# iqn_aid register map
Vendor: Texas Instruments
Peripheral module from a debugger description file (folder Keystone2).
Registers are 32-bit, read-only, no defined reset value unless marked. A register's access mark holds for its fields unless they carry their own. Offsets are as the file gives them; lines under a group give offsets from that group; [hi:lo] are bit positions; {n}, {i} and the like mark numbered series; 'fields as' and 'values as' point back to an identical list; <NAME> marks a mode.

## IQN_AID (part 1 of 2)
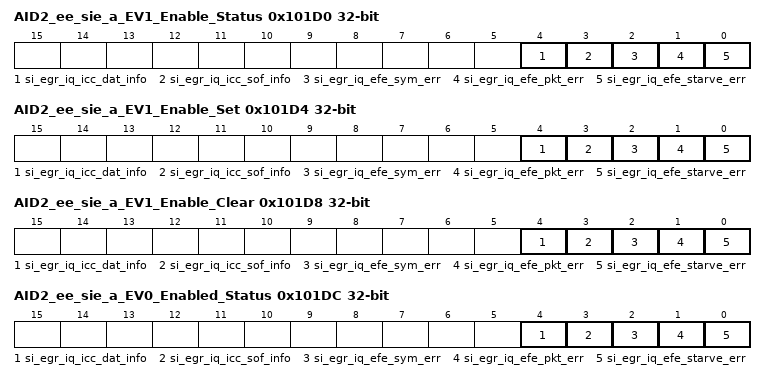
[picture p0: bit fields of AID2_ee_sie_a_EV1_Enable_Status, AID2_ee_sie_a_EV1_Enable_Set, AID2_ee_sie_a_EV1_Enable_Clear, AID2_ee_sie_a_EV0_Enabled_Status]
0x101D0 AID2_ee_sie_a_EV1_Enable_Status — (1 of 1, stride 0)
  [4] si_egr_iq_icc_dat_info — When set allows the corresponding bit in the raw_status register to generate the intr1_sts interrupt. Read only.
  [3] si_egr_iq_icc_sof_info — When set allows the corresponding bit in the raw_status register to generate the intr1_sts interrupt. Read only.
  [2] si_egr_iq_efe_sym_err — When set allows the corresponding bit in the raw_status register to generate the intr1_sts interrupt. Read only.
  [1] si_egr_iq_efe_pkt_err — When set allows the corresponding bit in the raw_status register to generate the intr1_sts interrupt. Read only.
  [0] si_egr_iq_efe_starve_err — When set allows the corresponding bit in the raw_status register to generate the intr1_sts interrupt. Read only.
0x101D4 AID2_ee_sie_a_EV1_Enable_Set wo — (1 of 1, stride 0)
  [4] si_egr_iq_icc_dat_info — Sets the corresponding bit in the intr1_status register when set. Write only, self-clears.
  [3] si_egr_iq_icc_sof_info — Sets the corresponding bit in the intr1_status register when set. Write only, self-clears.
  [2] si_egr_iq_efe_sym_err — Sets the corresponding bit in the intr1_status register when set. Write only, self-clears.
  [1] si_egr_iq_efe_pkt_err — Sets the corresponding bit in the intr1_status register when set. Write only, self-clears.
  [0] si_egr_iq_efe_starve_err — Sets the corresponding bit in the intr1_status register when set. Write only, self-clears.
0x101D8 AID2_ee_sie_a_EV1_Enable_Clear wo — (1 of 1, stride 0)
  [4] si_egr_iq_icc_dat_info — Clears the corresponding bit in the intr1_status register when set. Write only, self-clears.
  [3] si_egr_iq_icc_sof_info — Clears the corresponding bit in the intr1_status register when set. Write only, self-clears.
  [2] si_egr_iq_efe_sym_err — Clears the corresponding bit in the intr1_status register when set. Write only, self-clears.
  [1] si_egr_iq_efe_pkt_err — Clears the corresponding bit in the intr1_status register when set. Write only, self-clears.
  [0] si_egr_iq_efe_starve_err — Clears the corresponding bit in the intr1_status register when set. Write only, self-clears.
0x101DC AID2_ee_sie_a_EV0_Enabled_Status — (1 of 1, stride 0)
  [4] si_egr_iq_icc_dat_info — AND-ed raw_status bits with the corresponding bit in the enable_status register. Read only.
  [3] si_egr_iq_icc_sof_info — AND-ed raw_status bits with the corresponding bit in the enable_status register. Read only.
  [2] si_egr_iq_efe_sym_err — AND-ed raw_status bits with the corresponding bit in the enable_status register. Read only.
  [1] si_egr_iq_efe_pkt_err — AND-ed raw_status bits with the corresponding bit in the enable_status register. Read only.
  [0] si_egr_iq_efe_starve_err — AND-ed raw_status bits with the corresponding bit in the enable_status register. Read only.
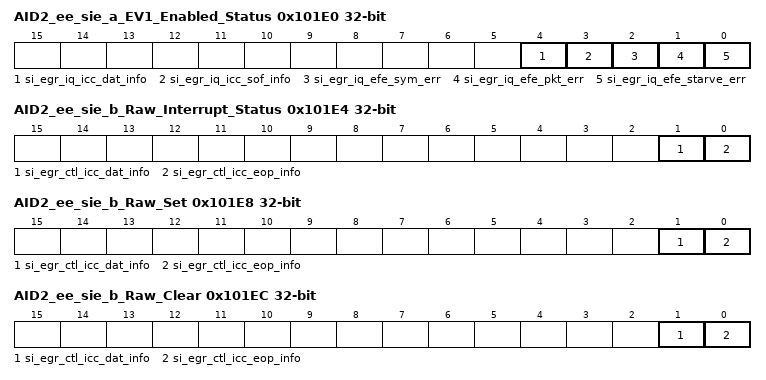
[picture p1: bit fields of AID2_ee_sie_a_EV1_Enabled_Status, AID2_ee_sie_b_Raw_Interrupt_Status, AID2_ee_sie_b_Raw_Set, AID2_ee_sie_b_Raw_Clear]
0x101E0 AID2_ee_sie_a_EV1_Enabled_Status — (1 of 1, stride 0)
  [4] si_egr_iq_icc_dat_info — AND-ed raw_status bits with the corresponding bit in the intr1_status register. Read only.
  [3] si_egr_iq_icc_sof_info — AND-ed raw_status bits with the corresponding bit in the intr1_status register. Read only.
  [2] si_egr_iq_efe_sym_err — AND-ed raw_status bits with the corresponding bit in the intr1_status register. Read only.
  [1] si_egr_iq_efe_pkt_err — AND-ed raw_status bits with the corresponding bit in the intr1_status register. Read only.
  [0] si_egr_iq_efe_starve_err — AND-ed raw_status bits with the corresponding bit in the intr1_status register. Read only.
0x101E4 AID2_ee_sie_b_Raw_Interrupt_Status — (1 of 1, stride 0)
  [1] si_egr_ctl_icc_dat_info — SI Egress CTL transmitted data to ICC
  [0] si_egr_ctl_icc_eop_info — SI Egress CTL transmitted EOP to ICC
0x101E8 AID2_ee_sie_b_Raw_Set wo — (1 of 1, stride 0)
  [1] si_egr_ctl_icc_dat_info — Sets the corresponding bit in the raw_status register when set. Write only, self-clears.
  [0] si_egr_ctl_icc_eop_info — Sets the corresponding bit in the raw_status register when set. Write only, self-clears.
0x101EC AID2_ee_sie_b_Raw_Clear wo — (1 of 1, stride 0)
  [1] si_egr_ctl_icc_dat_info — Clears the corresponding bit in the raw_status register when set. Write only, self-clears.
  [0] si_egr_ctl_icc_eop_info — Clears the corresponding bit in the raw_status register when set. Write only, self-clears.
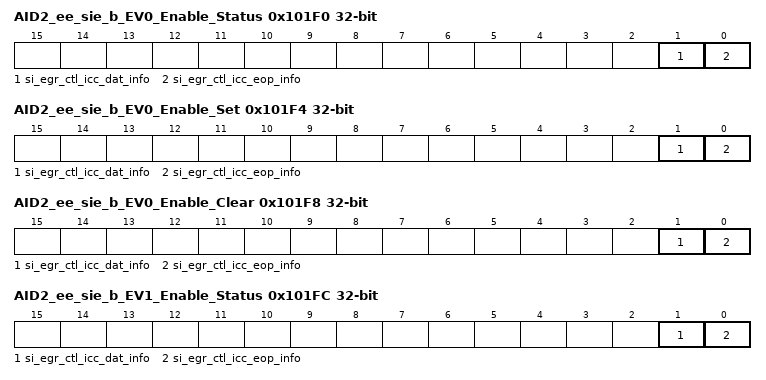
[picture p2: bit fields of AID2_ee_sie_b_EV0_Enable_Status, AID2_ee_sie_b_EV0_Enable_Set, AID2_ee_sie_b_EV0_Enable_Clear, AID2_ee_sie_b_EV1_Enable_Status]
0x101F0 AID2_ee_sie_b_EV0_Enable_Status — (1 of 1, stride 0)
  [1] si_egr_ctl_icc_dat_info — When set allows the corresponding bit in the raw_status register to generate the intr_sts interrupt. Read only.
  [0] si_egr_ctl_icc_eop_info — When set allows the corresponding bit in the raw_status register to generate the intr_sts interrupt. Read only.
0x101F4 AID2_ee_sie_b_EV0_Enable_Set wo — (1 of 1, stride 0)
  [1] si_egr_ctl_icc_dat_info — Sets the corresponding bit in the enable register when set. Write only, self-clears.
  [0] si_egr_ctl_icc_eop_info — Sets the corresponding bit in the enable register when set. Write only, self-clears.
0x101F8 AID2_ee_sie_b_EV0_Enable_Clear wo — (1 of 1, stride 0)
  [1] si_egr_ctl_icc_dat_info — Clears the corresponding bit in the enable register when set. Write only, self-clears.
  [0] si_egr_ctl_icc_eop_info — Clears the corresponding bit in the enable register when set. Write only, self-clears.
0x101FC AID2_ee_sie_b_EV1_Enable_Status — (1 of 1, stride 0)
  [1] si_egr_ctl_icc_dat_info — When set allows the corresponding bit in the raw_status register to generate the intr1_sts interrupt. Read only.
  [0] si_egr_ctl_icc_eop_info — When set allows the corresponding bit in the raw_status register to generate the intr1_sts interrupt. Read only.
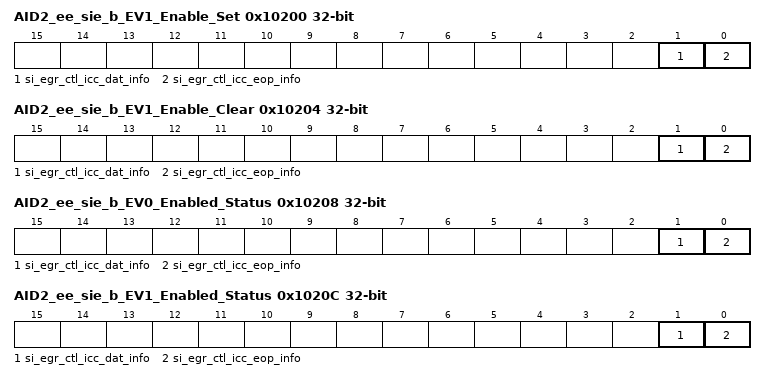
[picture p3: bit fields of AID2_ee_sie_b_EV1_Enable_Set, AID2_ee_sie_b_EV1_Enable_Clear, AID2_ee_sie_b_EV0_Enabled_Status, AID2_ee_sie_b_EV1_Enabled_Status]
0x10200 AID2_ee_sie_b_EV1_Enable_Set wo — (1 of 1, stride 0)
  [1] si_egr_ctl_icc_dat_info — Sets the corresponding bit in the intr1_status register when set. Write only, self-clears.
  [0] si_egr_ctl_icc_eop_info — Sets the corresponding bit in the intr1_status register when set. Write only, self-clears.
0x10204 AID2_ee_sie_b_EV1_Enable_Clear wo — (1 of 1, stride 0)
  [1] si_egr_ctl_icc_dat_info — Clears the corresponding bit in the intr1_status register when set. Write only, self-clears.
  [0] si_egr_ctl_icc_eop_info — Clears the corresponding bit in the intr1_status register when set. Write only, self-clears.
0x10208 AID2_ee_sie_b_EV0_Enabled_Status — (1 of 1, stride 0)
  [1] si_egr_ctl_icc_dat_info — AND-ed raw_status bits with the corresponding bit in the enable_status register. Read only.
  [0] si_egr_ctl_icc_eop_info — AND-ed raw_status bits with the corresponding bit in the enable_status register. Read only.
0x1020C AID2_ee_sie_b_EV1_Enabled_Status — (1 of 1, stride 0)
  [1] si_egr_ctl_icc_dat_info — AND-ed raw_status bits with the corresponding bit in the intr1_status register. Read only.
  [0] si_egr_ctl_icc_eop_info — AND-ed raw_status bits with the corresponding bit in the intr1_status register. Read only.
0x10210 AID2_ee_sie_c_Raw_Interrupt_Status — (1 of 1, stride 0)
  [15:0] si_egr_ctl_icc_sop_info — SI Egress CTL per channel SOP transmitted to ICC
0x10214 AID2_ee_sie_c_Raw_Set wo — (1 of 1, stride 0)
  [15:0] si_egr_ctl_icc_sop_info — Sets the corresponding bit in the raw_status register when set. Write only, self-clears.
0x10218 AID2_ee_sie_c_Raw_Clear wo — (1 of 1, stride 0)
  [15:0] si_egr_ctl_icc_sop_info — Clears the corresponding bit in the raw_status register when set. Write only, self-clears.
0x1021C AID2_ee_sie_c_EV0_Enable_Status — (1 of 1, stride 0)
  [15:0] si_egr_ctl_icc_sop_info — When set allows the corresponding bit in the raw_status register to generate the intr_sts interrupt. Read only.
0x10220 AID2_ee_sie_c_EV0_Enable_Set wo — (1 of 1, stride 0)
  [15:0] si_egr_ctl_icc_sop_info — Sets the corresponding bit in the enable register when set. Write only, self-clears.
0x10224 AID2_ee_sie_c_EV0_Enable_Clear wo — (1 of 1, stride 0)
  [15:0] si_egr_ctl_icc_sop_info — Clears the corresponding bit in the enable register when set. Write only, self-clears.
0x10228 AID2_ee_sie_c_EV1_Enable_Status — (1 of 1, stride 0)
  [15:0] si_egr_ctl_icc_sop_info — When set allows the corresponding bit in the raw_status register to generate the intr1_sts interrupt. Read only.
0x1022C AID2_ee_sie_c_EV1_Enable_Set wo — (1 of 1, stride 0)
  [15:0] si_egr_ctl_icc_sop_info — Sets the corresponding bit in the intr1_status register when set. Write only, self-clears.
0x10230 AID2_ee_sie_c_EV1_Enable_Clear wo — (1 of 1, stride 0)
  [15:0] si_egr_ctl_icc_sop_info — Clears the corresponding bit in the intr1_status register when set. Write only, self-clears.
0x10234 AID2_ee_sie_c_EV0_Enabled_Status — (1 of 1, stride 0)
  [15:0] si_egr_ctl_icc_sop_info — AND-ed raw_status bits with the corresponding bit in the enable_status register. Read only.
0x10238 AID2_ee_sie_c_EV1_Enabled_Status — (1 of 1, stride 0)
  [15:0] si_egr_ctl_icc_sop_info — AND-ed raw_status bits with the corresponding bit in the intr1_status register. Read only.
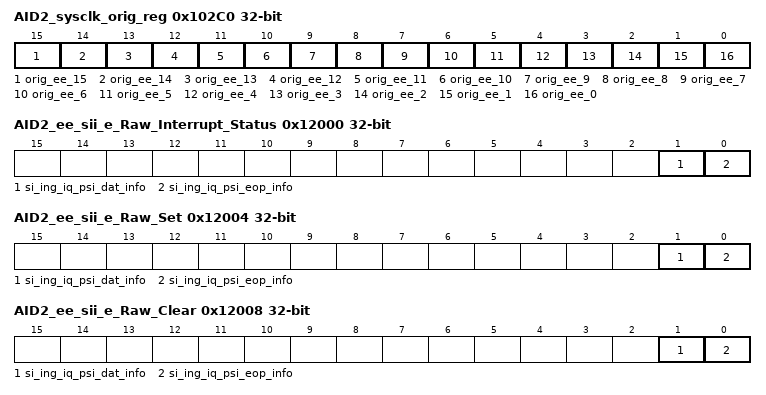
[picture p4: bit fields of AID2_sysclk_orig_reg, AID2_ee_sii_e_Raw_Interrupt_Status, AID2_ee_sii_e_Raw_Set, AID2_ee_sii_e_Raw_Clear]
0x102C0 AID2_sysclk_orig_reg — (1 of 1, stride 0)
  [15] orig_ee_15 — Undefined for AID2. Always read as 0.
  [14] orig_ee_14 — Undefined for AID2. Always read as 0.
  [13] orig_ee_13 — Undefined for AID2. Always read as 0.
  [12] orig_ee_12 — If set a bit is set in the ee_sie_c register.
  [11] orig_ee_11 — If set a bit is set in the ee_sie_b register.
  [10] orig_ee_10 — If set a bit is set in the ee_sie_a register.
  [9] orig_ee_9 — Undefined for AID2. Always read as 0.
  [8] orig_ee_8 — Undefined for AID2. Always read as 0.
  [7] orig_ee_7 — Undefined for AID2. Always read as 0.
  [6] orig_ee_6 — If set a bit is set in the ee_sii_d register.
  [5] orig_ee_5 — Undefined for AID2. Always read as 0.
  [4] orig_ee_4 — Undefined for AID2. Always read as 0.
  [3] orig_ee_3 — Undefined for AID2. Always read as 0.
  [2] orig_ee_2 — If set a bit is set in the ee_sii_c register.
  [1] orig_ee_1 — If set a bit is set in the ee_sii_b register.
  [0] orig_ee_0 — If set a bit is set in the ee_sii_a register.
0x11000 AID2_dfe_ee_a_Raw_Interrupt_Status — (1 of 1, stride 0)
  [1:0] dfe_iqn_aid2_err — DFE error interrupts
0x11004 AID2_dfe_ee_a_Raw_Set wo — (1 of 1, stride 0)
  [1:0] dfe_iqn_aid2_err — Sets the corresponding bit in the raw_status register when set. Write only, self-clears.
0x11008 AID2_dfe_ee_a_Raw_Clear wo — (1 of 1, stride 0)
  [1:0] dfe_iqn_aid2_err — Clears the corresponding bit in the raw_status register when set. Write only, self-clears.
0x1100C AID2_dfe_ee_a_EV0_Enable_Status — (1 of 1, stride 0)
  [1:0] dfe_iqn_aid2_err — When set allows the corresponding bit in the raw_status register to generate the intr_sts interrupt. Read only.
0x11010 AID2_dfe_ee_a_EV0_Enable_Set wo — (1 of 1, stride 0)
  [1:0] dfe_iqn_aid2_err — Sets the corresponding bit in the enable register when set. Write only, self-clears.
0x11014 AID2_dfe_ee_a_EV0_Enable_Clear wo — (1 of 1, stride 0)
  [1:0] dfe_iqn_aid2_err — Clears the corresponding bit in the enable register when set. Write only, self-clears.
0x11018 AID2_dfe_ee_a_EV1_Enable_Status — (1 of 1, stride 0)
  [1:0] dfe_iqn_aid2_err — When set allows the corresponding bit in the raw_status register to generate the intr1_sts interrupt. Read only.
0x1101C AID2_dfe_ee_a_EV1_Enable_Set wo — (1 of 1, stride 0)
  [1:0] dfe_iqn_aid2_err — Sets the corresponding bit in the intr1_status register when set. Write only, self-clears.
0x11020 AID2_dfe_ee_a_EV1_Enable_Clear wo — (1 of 1, stride 0)
  [1:0] dfe_iqn_aid2_err — Clears the corresponding bit in the intr1_status register when set. Write only, self-clears.
0x11024 AID2_dfe_ee_a_EV0_Enabled_Status — (1 of 1, stride 0)
  [1:0] dfe_iqn_aid2_err — AND-ed raw_status bits with the corresponding bit in the enable_status register. Read only.
0x11028 AID2_dfe_ee_a_EV1_Enabled_Status — (1 of 1, stride 0)
  [1:0] dfe_iqn_aid2_err — AND-ed raw_status bits with the corresponding bit in the intr1_status register. Read only.
0x12000 AID2_ee_sii_e_Raw_Interrupt_Status — (1 of 1, stride 0)
  [1] si_ing_iq_psi_dat_info — SI Ingress IQ data transmitted to PSI
  [0] si_ing_iq_psi_eop_info — SI Ingress IQ EOP transmitted to PSI
0x12004 AID2_ee_sii_e_Raw_Set wo — (1 of 1, stride 0)
  [1] si_ing_iq_psi_dat_info — Sets the corresponding bit in the raw_status register when set. Write only, self-clears.
  [0] si_ing_iq_psi_eop_info — Sets the corresponding bit in the raw_status register when set. Write only, self-clears.
0x12008 AID2_ee_sii_e_Raw_Clear wo — (1 of 1, stride 0)
  [1] si_ing_iq_psi_dat_info — Clears the corresponding bit in the raw_status register when set. Write only, self-clears.
  [0] si_ing_iq_psi_eop_info — Clears the corresponding bit in the raw_status register when set. Write only, self-clears.
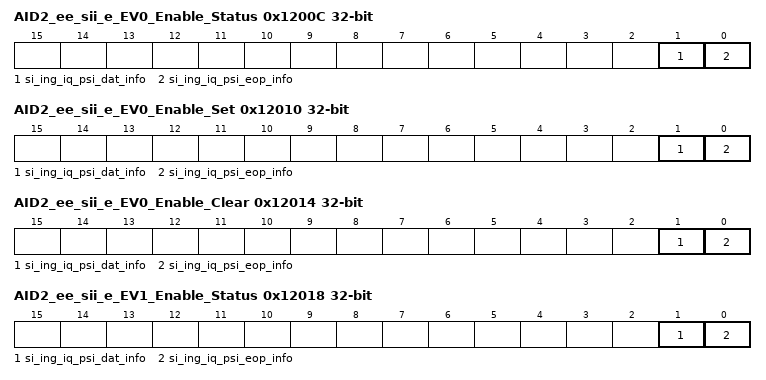
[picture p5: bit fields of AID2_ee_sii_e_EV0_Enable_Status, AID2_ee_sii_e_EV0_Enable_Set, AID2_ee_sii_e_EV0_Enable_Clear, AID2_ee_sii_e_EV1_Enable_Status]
0x1200C AID2_ee_sii_e_EV0_Enable_Status — (1 of 1, stride 0)
  [1] si_ing_iq_psi_dat_info — When set allows the corresponding bit in the raw_status register to generate the intr_sts interrupt. Read only.
  [0] si_ing_iq_psi_eop_info — When set allows the corresponding bit in the raw_status register to generate the intr_sts interrupt. Read only.
0x12010 AID2_ee_sii_e_EV0_Enable_Set wo — (1 of 1, stride 0)
  [1] si_ing_iq_psi_dat_info — Sets the corresponding bit in the enable register when set. Write only, self-clears.
  [0] si_ing_iq_psi_eop_info — Sets the corresponding bit in the enable register when set. Write only, self-clears.
0x12014 AID2_ee_sii_e_EV0_Enable_Clear wo — (1 of 1, stride 0)
  [1] si_ing_iq_psi_dat_info — Clears the corresponding bit in the enable register when set. Write only, self-clears.
  [0] si_ing_iq_psi_eop_info — Clears the corresponding bit in the enable register when set. Write only, self-clears.
0x12018 AID2_ee_sii_e_EV1_Enable_Status — (1 of 1, stride 0)
  [1] si_ing_iq_psi_dat_info — When set allows the corresponding bit in the raw_status register to generate the intr1_sts interrupt. Read only.
  [0] si_ing_iq_psi_eop_info — When set allows the corresponding bit in the raw_status register to generate the intr1_sts interrupt. Read only.
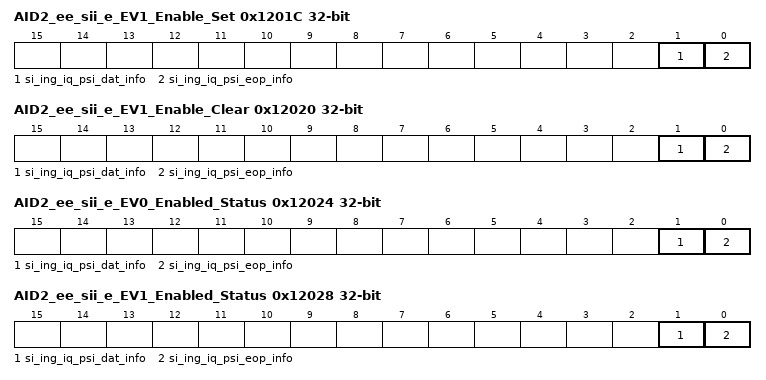
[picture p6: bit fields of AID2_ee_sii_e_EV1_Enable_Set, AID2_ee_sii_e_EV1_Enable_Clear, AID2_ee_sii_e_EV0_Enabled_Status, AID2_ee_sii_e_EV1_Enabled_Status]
0x1201C AID2_ee_sii_e_EV1_Enable_Set wo — (1 of 1, stride 0)
  [1] si_ing_iq_psi_dat_info — Sets the corresponding bit in the intr1_status register when set. Write only, self-clears.
  [0] si_ing_iq_psi_eop_info — Sets the corresponding bit in the intr1_status register when set. Write only, self-clears.
0x12020 AID2_ee_sii_e_EV1_Enable_Clear wo — (1 of 1, stride 0)
  [1] si_ing_iq_psi_dat_info — Clears the corresponding bit in the intr1_status register when set. Write only, self-clears.
  [0] si_ing_iq_psi_eop_info — Clears the corresponding bit in the intr1_status register when set. Write only, self-clears.
0x12024 AID2_ee_sii_e_EV0_Enabled_Status — (1 of 1, stride 0)
  [1] si_ing_iq_psi_dat_info — AND-ed raw_status bits with the corresponding bit in the enable_status register. Read only.
  [0] si_ing_iq_psi_eop_info — AND-ed raw_status bits with the corresponding bit in the enable_status register. Read only.
0x12028 AID2_ee_sii_e_EV1_Enabled_Status — (1 of 1, stride 0)
  [1] si_ing_iq_psi_dat_info — AND-ed raw_status bits with the corresponding bit in the intr1_status register. Read only.
  [0] si_ing_iq_psi_eop_info — AND-ed raw_status bits with the corresponding bit in the intr1_status register. Read only.
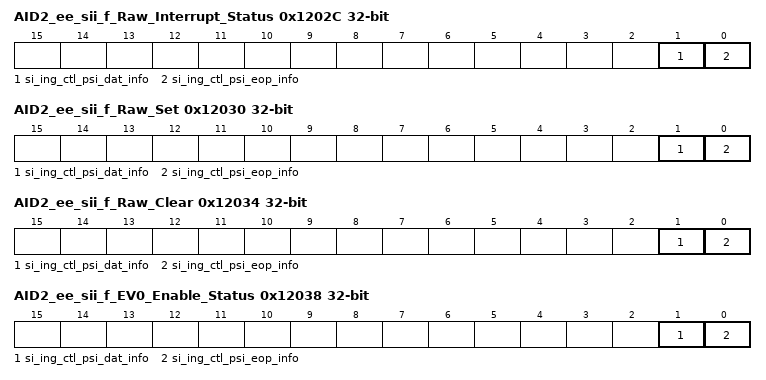
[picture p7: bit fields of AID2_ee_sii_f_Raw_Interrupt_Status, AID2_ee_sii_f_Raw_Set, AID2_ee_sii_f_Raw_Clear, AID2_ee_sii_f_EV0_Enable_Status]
0x1202C AID2_ee_sii_f_Raw_Interrupt_Status — (1 of 1, stride 0)
  [1] si_ing_ctl_psi_dat_info — SI Ingress CTL data transmitted to PSI
  [0] si_ing_ctl_psi_eop_info — SI Ingress CTL EOP transmitted to PSI
0x12030 AID2_ee_sii_f_Raw_Set wo — (1 of 1, stride 0)
  [1] si_ing_ctl_psi_dat_info — Sets the corresponding bit in the raw_status register when set. Write only, self-clears.
  [0] si_ing_ctl_psi_eop_info — Sets the corresponding bit in the raw_status register when set. Write only, self-clears.
0x12034 AID2_ee_sii_f_Raw_Clear wo — (1 of 1, stride 0)
  [1] si_ing_ctl_psi_dat_info — Clears the corresponding bit in the raw_status register when set. Write only, self-clears.
  [0] si_ing_ctl_psi_eop_info — Clears the corresponding bit in the raw_status register when set. Write only, self-clears.
0x12038 AID2_ee_sii_f_EV0_Enable_Status — (1 of 1, stride 0)
  [1] si_ing_ctl_psi_dat_info — When set allows the corresponding bit in the raw_status register to generate the intr_sts interrupt. Read only.
  [0] si_ing_ctl_psi_eop_info — When set allows the corresponding bit in the raw_status register to generate the intr_sts interrupt. Read only.
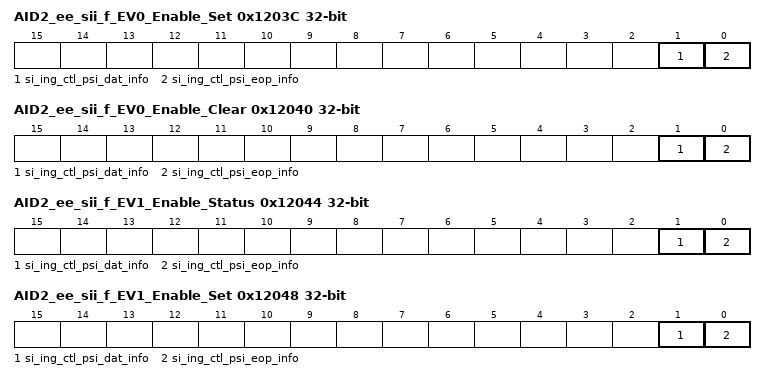
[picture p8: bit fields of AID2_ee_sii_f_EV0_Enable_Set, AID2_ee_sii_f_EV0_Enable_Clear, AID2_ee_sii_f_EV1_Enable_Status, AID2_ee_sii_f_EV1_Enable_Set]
0x1203C AID2_ee_sii_f_EV0_Enable_Set wo — (1 of 1, stride 0)
  [1] si_ing_ctl_psi_dat_info — Sets the corresponding bit in the enable register when set. Write only, self-clears.
  [0] si_ing_ctl_psi_eop_info — Sets the corresponding bit in the enable register when set. Write only, self-clears.
0x12040 AID2_ee_sii_f_EV0_Enable_Clear wo — (1 of 1, stride 0)
  [1] si_ing_ctl_psi_dat_info — Clears the corresponding bit in the enable register when set. Write only, self-clears.
  [0] si_ing_ctl_psi_eop_info — Clears the corresponding bit in the enable register when set. Write only, self-clears.
0x12044 AID2_ee_sii_f_EV1_Enable_Status — (1 of 1, stride 0)
  [1] si_ing_ctl_psi_dat_info — When set allows the corresponding bit in the raw_status register to generate the intr1_sts interrupt. Read only.
  [0] si_ing_ctl_psi_eop_info — When set allows the corresponding bit in the raw_status register to generate the intr1_sts interrupt. Read only.
0x12048 AID2_ee_sii_f_EV1_Enable_Set wo — (1 of 1, stride 0)
  [1] si_ing_ctl_psi_dat_info — Sets the corresponding bit in the intr1_status register when set. Write only, self-clears.
  [0] si_ing_ctl_psi_eop_info — Sets the corresponding bit in the intr1_status register when set. Write only, self-clears.
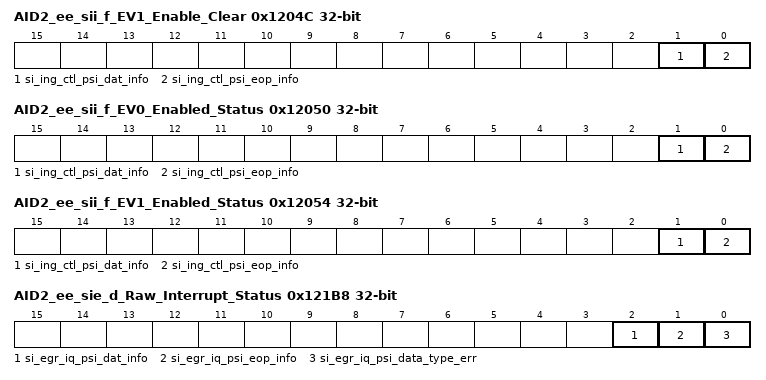
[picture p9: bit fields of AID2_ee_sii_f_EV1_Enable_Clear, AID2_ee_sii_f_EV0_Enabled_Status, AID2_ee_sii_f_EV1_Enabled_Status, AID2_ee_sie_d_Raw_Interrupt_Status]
0x1204C AID2_ee_sii_f_EV1_Enable_Clear wo — (1 of 1, stride 0)
  [1] si_ing_ctl_psi_dat_info — Clears the corresponding bit in the intr1_status register when set. Write only, self-clears.
  [0] si_ing_ctl_psi_eop_info — Clears the corresponding bit in the intr1_status register when set. Write only, self-clears.
0x12050 AID2_ee_sii_f_EV0_Enabled_Status — (1 of 1, stride 0)
  [1] si_ing_ctl_psi_dat_info — AND-ed raw_status bits with the corresponding bit in the enable_status register. Read only.
  [0] si_ing_ctl_psi_eop_info — AND-ed raw_status bits with the corresponding bit in the enable_status register. Read only.
0x12054 AID2_ee_sii_f_EV1_Enabled_Status — (1 of 1, stride 0)
  [1] si_ing_ctl_psi_dat_info — AND-ed raw_status bits with the corresponding bit in the intr1_status register. Read only.
  [0] si_ing_ctl_psi_eop_info — AND-ed raw_status bits with the corresponding bit in the intr1_status register. Read only.
0x12058 AID2_ee_sii_g_Raw_Interrupt_Status — (1 of 1, stride 0)
  [31:0] si_ing_iq_psi_sop_info — SI Ingress IQ SOP transmitted to PSI
0x1205C AID2_ee_sii_g_Raw_Set wo — (1 of 1, stride 0)
  [31:0] si_ing_iq_psi_sop_info — Sets the corresponding bit in the raw_status register when set. Write only, self-clears.
0x12060 AID2_ee_sii_g_Raw_Clear wo — (1 of 1, stride 0)
  [31:0] si_ing_iq_psi_sop_info — Clears the corresponding bit in the raw_status register when set. Write only, self-clears.
0x12064 AID2_ee_sii_g_EV0_Enable_Status — (1 of 1, stride 0)
  [31:0] si_ing_iq_psi_sop_info — When set allows the corresponding bit in the raw_status register to generate the intr_sts interrupt. Read only.
0x12068 AID2_ee_sii_g_EV0_Enable_Set wo — (1 of 1, stride 0)
  [31:0] si_ing_iq_psi_sop_info — Sets the corresponding bit in the enable register when set. Write only, self-clears.
0x1206C AID2_ee_sii_g_EV0_Enable_Clear wo — (1 of 1, stride 0)
  [31:0] si_ing_iq_psi_sop_info — Clears the corresponding bit in the enable register when set. Write only, self-clears.
0x12070 AID2_ee_sii_g_EV1_Enable_Status — (1 of 1, stride 0)
  [31:0] si_ing_iq_psi_sop_info — When set allows the corresponding bit in the raw_status register to generate the intr1_sts interrupt. Read only.
0x12074 AID2_ee_sii_g_EV1_Enable_Set wo — (1 of 1, stride 0)
  [31:0] si_ing_iq_psi_sop_info — Sets the corresponding bit in the intr1_status register when set. Write only, self-clears.
0x12078 AID2_ee_sii_g_EV1_Enable_Clear wo — (1 of 1, stride 0)
  [31:0] si_ing_iq_psi_sop_info — Clears the corresponding bit in the intr1_status register when set. Write only, self-clears.
0x1207C AID2_ee_sii_g_EV0_Enabled_Status — (1 of 1, stride 0)
  [31:0] si_ing_iq_psi_sop_info — AND-ed raw_status bits with the corresponding bit in the enable_status register. Read only.
0x12080 AID2_ee_sii_g_EV1_Enabled_Status — (1 of 1, stride 0)
  [31:0] si_ing_iq_psi_sop_info — AND-ed raw_status bits with the corresponding bit in the intr1_status register. Read only.
0x12108 AID2_ee_sii_h_Raw_Interrupt_Status — (1 of 1, stride 0)
  [15:0] si_ing_ctl_psi_sop_info — SI Ingress CTL per channel SOP transmitted to PSI
0x1210C AID2_ee_sii_h_Raw_Set wo — (1 of 1, stride 0)
  [15:0] si_ing_ctl_psi_sop_info — Sets the corresponding bit in the raw_status register when set. Write only, self-clears.
0x12110 AID2_ee_sii_h_Raw_Clear wo — (1 of 1, stride 0)
  [15:0] si_ing_ctl_psi_sop_info — Clears the corresponding bit in the raw_status register when set. Write only, self-clears.
0x12114 AID2_ee_sii_h_EV0_Enable_Status — (1 of 1, stride 0)
  [15:0] si_ing_ctl_psi_sop_info — When set allows the corresponding bit in the raw_status register to generate the intr_sts interrupt. Read only.
0x12118 AID2_ee_sii_h_EV0_Enable_Set wo — (1 of 1, stride 0)
  [15:0] si_ing_ctl_psi_sop_info — Sets the corresponding bit in the enable register when set. Write only, self-clears.
0x1211C AID2_ee_sii_h_EV0_Enable_Clear wo — (1 of 1, stride 0)
  [15:0] si_ing_ctl_psi_sop_info — Clears the corresponding bit in the enable register when set. Write only, self-clears.
0x12120 AID2_ee_sii_h_EV1_Enable_Status — (1 of 1, stride 0)
  [15:0] si_ing_ctl_psi_sop_info — When set allows the corresponding bit in the raw_status register to generate the intr1_sts interrupt. Read only.
0x12124 AID2_ee_sii_h_EV1_Enable_Set wo — (1 of 1, stride 0)
  [15:0] si_ing_ctl_psi_sop_info — Sets the corresponding bit in the intr1_status register when set. Write only, self-clears.
0x12128 AID2_ee_sii_h_EV1_Enable_Clear wo — (1 of 1, stride 0)
  [15:0] si_ing_ctl_psi_sop_info — Clears the corresponding bit in the intr1_status register when set. Write only, self-clears.
0x1212C AID2_ee_sii_h_EV0_Enabled_Status — (1 of 1, stride 0)
  [15:0] si_ing_ctl_psi_sop_info — AND-ed raw_status bits with the corresponding bit in the enable_status register. Read only.
0x12130 AID2_ee_sii_h_EV1_Enabled_Status — (1 of 1, stride 0)
  [15:0] si_ing_ctl_psi_sop_info — AND-ed raw_status bits with the corresponding bit in the intr1_status register. Read only.
0x121B8 AID2_ee_sie_d_Raw_Interrupt_Status — (1 of 1, stride 0)
  [2] si_egr_iq_psi_dat_info — SI Egress IQ valid data received from PSI
  [1] si_egr_iq_psi_eop_info — SI Egress IQ EOP received from PSI
  [0] si_egr_iq_psi_data_type_err — SI Egress IQ PSI data type error
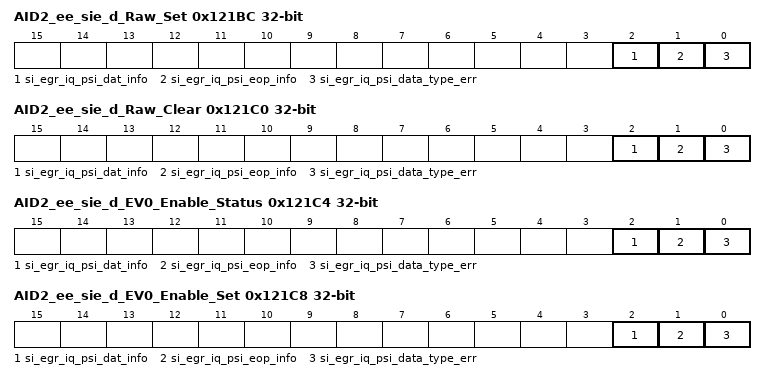
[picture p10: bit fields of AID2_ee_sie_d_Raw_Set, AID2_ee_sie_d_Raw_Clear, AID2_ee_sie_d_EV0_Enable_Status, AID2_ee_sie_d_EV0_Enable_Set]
0x121BC AID2_ee_sie_d_Raw_Set wo — (1 of 1, stride 0)
  [2] si_egr_iq_psi_dat_info — Sets the corresponding bit in the raw_status register when set. Write only, self-clears.
  [1] si_egr_iq_psi_eop_info — Sets the corresponding bit in the raw_status register when set. Write only, self-clears.
  [0] si_egr_iq_psi_data_type_err — Sets the corresponding bit in the raw_status register when set. Write only, self-clears.
0x121C0 AID2_ee_sie_d_Raw_Clear wo — (1 of 1, stride 0)
  [2] si_egr_iq_psi_dat_info — Clears the corresponding bit in the raw_status register when set. Write only, self-clears.
  [1] si_egr_iq_psi_eop_info — Clears the corresponding bit in the raw_status register when set. Write only, self-clears.
  [0] si_egr_iq_psi_data_type_err — Clears the corresponding bit in the raw_status register when set. Write only, self-clears.
0x121C4 AID2_ee_sie_d_EV0_Enable_Status — (1 of 1, stride 0)
  [2] si_egr_iq_psi_dat_info — When set allows the corresponding bit in the raw_status register to generate the intr_sts interrupt. Read only.
  [1] si_egr_iq_psi_eop_info — When set allows the corresponding bit in the raw_status register to generate the intr_sts interrupt. Read only.
  [0] si_egr_iq_psi_data_type_err — When set allows the corresponding bit in the raw_status register to generate the intr_sts interrupt. Read only.
0x121C8 AID2_ee_sie_d_EV0_Enable_Set wo — (1 of 1, stride 0)
  [2] si_egr_iq_psi_dat_info — Sets the corresponding bit in the enable register when set. Write only, self-clears.
  [1] si_egr_iq_psi_eop_info — Sets the corresponding bit in the enable register when set. Write only, self-clears.
  [0] si_egr_iq_psi_data_type_err — Sets the corresponding bit in the enable register when set. Write only, self-clears.
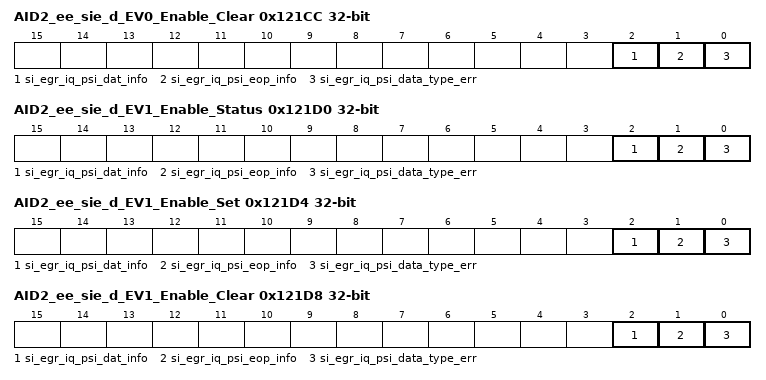
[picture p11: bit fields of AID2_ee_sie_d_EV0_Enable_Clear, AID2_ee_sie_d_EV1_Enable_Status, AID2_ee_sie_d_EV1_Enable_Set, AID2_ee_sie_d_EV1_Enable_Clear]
0x121CC AID2_ee_sie_d_EV0_Enable_Clear wo — (1 of 1, stride 0)
  [2] si_egr_iq_psi_dat_info — Clears the corresponding bit in the enable register when set. Write only, self-clears.
  [1] si_egr_iq_psi_eop_info — Clears the corresponding bit in the enable register when set. Write only, self-clears.
  [0] si_egr_iq_psi_data_type_err — Clears the corresponding bit in the enable register when set. Write only, self-clears.
0x121D0 AID2_ee_sie_d_EV1_Enable_Status — (1 of 1, stride 0)
  [2] si_egr_iq_psi_dat_info — When set allows the corresponding bit in the raw_status register to generate the intr1_sts interrupt. Read only.
  [1] si_egr_iq_psi_eop_info — When set allows the corresponding bit in the raw_status register to generate the intr1_sts interrupt. Read only.
  [0] si_egr_iq_psi_data_type_err — When set allows the corresponding bit in the raw_status register to generate the intr1_sts interrupt. Read only.
0x121D4 AID2_ee_sie_d_EV1_Enable_Set wo — (1 of 1, stride 0)
  [2] si_egr_iq_psi_dat_info — Sets the corresponding bit in the intr1_status register when set. Write only, self-clears.
  [1] si_egr_iq_psi_eop_info — Sets the corresponding bit in the intr1_status register when set. Write only, self-clears.
  [0] si_egr_iq_psi_data_type_err — Sets the corresponding bit in the intr1_status register when set. Write only, self-clears.
0x121D8 AID2_ee_sie_d_EV1_Enable_Clear wo — (1 of 1, stride 0)
  [2] si_egr_iq_psi_dat_info — Clears the corresponding bit in the intr1_status register when set. Write only, self-clears.
  [1] si_egr_iq_psi_eop_info — Clears the corresponding bit in the intr1_status register when set. Write only, self-clears.
  [0] si_egr_iq_psi_data_type_err — Clears the corresponding bit in the intr1_status register when set. Write only, self-clears.
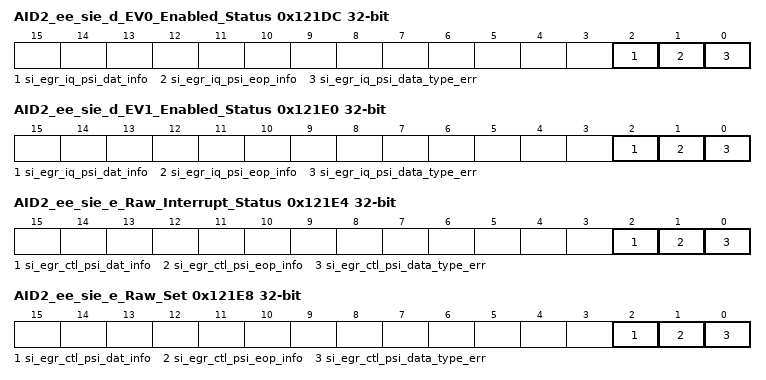
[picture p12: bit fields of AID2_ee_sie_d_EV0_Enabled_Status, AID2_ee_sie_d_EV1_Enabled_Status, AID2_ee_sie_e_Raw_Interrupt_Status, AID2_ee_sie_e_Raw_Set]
0x121DC AID2_ee_sie_d_EV0_Enabled_Status — (1 of 1, stride 0)
  [2] si_egr_iq_psi_dat_info — AND-ed raw_status bits with the corresponding bit in the enable_status register. Read only.
  [1] si_egr_iq_psi_eop_info — AND-ed raw_status bits with the corresponding bit in the enable_status register. Read only.
  [0] si_egr_iq_psi_data_type_err — AND-ed raw_status bits with the corresponding bit in the enable_status register. Read only.
0x121E0 AID2_ee_sie_d_EV1_Enabled_Status — (1 of 1, stride 0)
  [2] si_egr_iq_psi_dat_info — AND-ed raw_status bits with the corresponding bit in the intr1_status register. Read only.
  [1] si_egr_iq_psi_eop_info — AND-ed raw_status bits with the corresponding bit in the intr1_status register. Read only.
  [0] si_egr_iq_psi_data_type_err — AND-ed raw_status bits with the corresponding bit in the intr1_status register. Read only.
0x121E4 AID2_ee_sie_e_Raw_Interrupt_Status — (1 of 1, stride 0)
  [2] si_egr_ctl_psi_dat_info — SI Egress CTL valid data received from PSI
  [1] si_egr_ctl_psi_eop_info — SI Egress CTL EOP received from PSI
  [0] si_egr_ctl_psi_data_type_err — SI Egress CTL PSI data type error
0x121E8 AID2_ee_sie_e_Raw_Set wo — (1 of 1, stride 0)
  [2] si_egr_ctl_psi_dat_info — Sets the corresponding bit in the raw_status register when set. Write only, self-clears.
  [1] si_egr_ctl_psi_eop_info — Sets the corresponding bit in the raw_status register when set. Write only, self-clears.
  [0] si_egr_ctl_psi_data_type_err — Sets the corresponding bit in the raw_status register when set. Write only, self-clears.
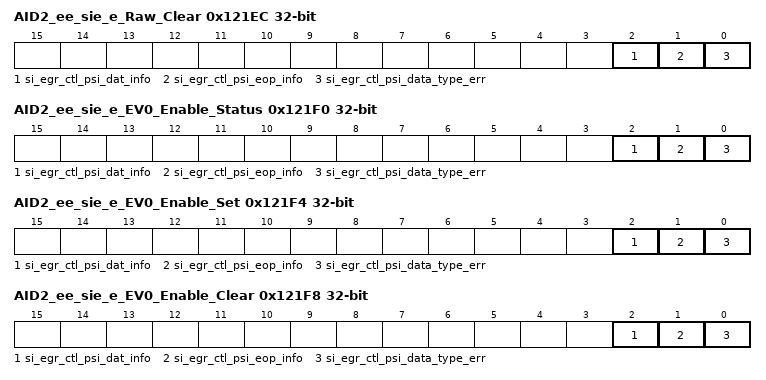
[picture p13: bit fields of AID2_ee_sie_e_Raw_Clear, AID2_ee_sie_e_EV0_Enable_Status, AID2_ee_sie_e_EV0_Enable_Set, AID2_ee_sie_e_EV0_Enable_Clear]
0x121EC AID2_ee_sie_e_Raw_Clear wo — (1 of 1, stride 0)
  [2] si_egr_ctl_psi_dat_info — Clears the corresponding bit in the raw_status register when set. Write only, self-clears.
  [1] si_egr_ctl_psi_eop_info — Clears the corresponding bit in the raw_status register when set. Write only, self-clears.
  [0] si_egr_ctl_psi_data_type_err — Clears the corresponding bit in the raw_status register when set. Write only, self-clears.
0x121F0 AID2_ee_sie_e_EV0_Enable_Status — (1 of 1, stride 0)
  [2] si_egr_ctl_psi_dat_info — When set allows the corresponding bit in the raw_status register to generate the intr_sts interrupt. Read only.
  [1] si_egr_ctl_psi_eop_info — When set allows the corresponding bit in the raw_status register to generate the intr_sts interrupt. Read only.
  [0] si_egr_ctl_psi_data_type_err — When set allows the corresponding bit in the raw_status register to generate the intr_sts interrupt. Read only.
0x121F4 AID2_ee_sie_e_EV0_Enable_Set wo — (1 of 1, stride 0)
  [2] si_egr_ctl_psi_dat_info — Sets the corresponding bit in the enable register when set. Write only, self-clears.
  [1] si_egr_ctl_psi_eop_info — Sets the corresponding bit in the enable register when set. Write only, self-clears.
  [0] si_egr_ctl_psi_data_type_err — Sets the corresponding bit in the enable register when set. Write only, self-clears.
0x121F8 AID2_ee_sie_e_EV0_Enable_Clear wo — (1 of 1, stride 0)
  [2] si_egr_ctl_psi_dat_info — Clears the corresponding bit in the enable register when set. Write only, self-clears.
  [1] si_egr_ctl_psi_eop_info — Clears the corresponding bit in the enable register when set. Write only, self-clears.
  [0] si_egr_ctl_psi_data_type_err — Clears the corresponding bit in the enable register when set. Write only, self-clears.
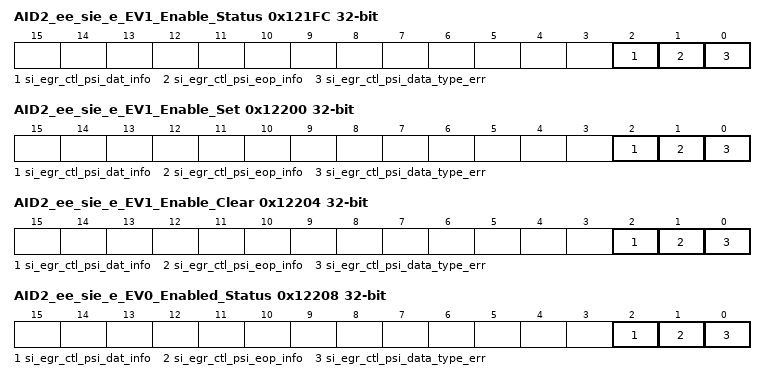
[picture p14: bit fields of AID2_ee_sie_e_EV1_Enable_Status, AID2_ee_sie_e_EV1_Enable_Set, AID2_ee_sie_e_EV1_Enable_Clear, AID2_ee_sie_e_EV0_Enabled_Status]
0x121FC AID2_ee_sie_e_EV1_Enable_Status — (1 of 1, stride 0)
  [2] si_egr_ctl_psi_dat_info — When set allows the corresponding bit in the raw_status register to generate the intr1_sts interrupt. Read only.
  [1] si_egr_ctl_psi_eop_info — When set allows the corresponding bit in the raw_status register to generate the intr1_sts interrupt. Read only.
  [0] si_egr_ctl_psi_data_type_err — When set allows the corresponding bit in the raw_status register to generate the intr1_sts interrupt. Read only.
0x12200 AID2_ee_sie_e_EV1_Enable_Set wo — (1 of 1, stride 0)
  [2] si_egr_ctl_psi_dat_info — Sets the corresponding bit in the intr1_status register when set. Write only, self-clears.
  [1] si_egr_ctl_psi_eop_info — Sets the corresponding bit in the intr1_status register when set. Write only, self-clears.
  [0] si_egr_ctl_psi_data_type_err — Sets the corresponding bit in the intr1_status register when set. Write only, self-clears.
0x12204 AID2_ee_sie_e_EV1_Enable_Clear wo — (1 of 1, stride 0)
  [2] si_egr_ctl_psi_dat_info — Clears the corresponding bit in the intr1_status register when set. Write only, self-clears.
  [1] si_egr_ctl_psi_eop_info — Clears the corresponding bit in the intr1_status register when set. Write only, self-clears.
  [0] si_egr_ctl_psi_data_type_err — Clears the corresponding bit in the intr1_status register when set. Write only, self-clears.
0x12208 AID2_ee_sie_e_EV0_Enabled_Status — (1 of 1, stride 0)
  [2] si_egr_ctl_psi_dat_info — AND-ed raw_status bits with the corresponding bit in the enable_status register. Read only.
  [1] si_egr_ctl_psi_eop_info — AND-ed raw_status bits with the corresponding bit in the enable_status register. Read only.
  [0] si_egr_ctl_psi_data_type_err — AND-ed raw_status bits with the corresponding bit in the enable_status register. Read only.
0x1220C AID2_ee_sie_e_EV1_Enabled_Status — (1 of 1, stride 0)
  [2] si_egr_ctl_psi_dat_info — AND-ed raw_status bits with the corresponding bit in the intr1_status register. Read only.
  [1] si_egr_ctl_psi_eop_info — AND-ed raw_status bits with the corresponding bit in the intr1_status register. Read only.
  [0] si_egr_ctl_psi_data_type_err — AND-ed raw_status bits with the corresponding bit in the intr1_status register. Read only.
0x12210 AID2_ee_sie_f_Raw_Interrupt_Status — (1 of 1, stride 0)
  [31:0] si_egr_iq_psi_sop_info — SI Ingress IQ per channel SOP received from PSI
0x12214 AID2_ee_sie_f_Raw_Set wo — (1 of 1, stride 0)
  [31:0] si_egr_iq_psi_sop_info — Sets the corresponding bit in the raw_status register when set. Write only, self-clears.
0x12218 AID2_ee_sie_f_Raw_Clear wo — (1 of 1, stride 0)
  [31:0] si_egr_iq_psi_sop_info — Clears the corresponding bit in the raw_status register when set. Write only, self-clears.
0x1221C AID2_ee_sie_f_EV0_Enable_Status — (1 of 1, stride 0)
  [31:0] si_egr_iq_psi_sop_info — When set allows the corresponding bit in the raw_status register to generate the intr_sts interrupt. Read only.
0x12220 AID2_ee_sie_f_EV0_Enable_Set wo — (1 of 1, stride 0)
  [31:0] si_egr_iq_psi_sop_info — Sets the corresponding bit in the enable register when set. Write only, self-clears.
0x12224 AID2_ee_sie_f_EV0_Enable_Clear wo — (1 of 1, stride 0)
  [31:0] si_egr_iq_psi_sop_info — Clears the corresponding bit in the enable register when set. Write only, self-clears.
0x12228 AID2_ee_sie_f_EV1_Enable_Status — (1 of 1, stride 0)
  [31:0] si_egr_iq_psi_sop_info — When set allows the corresponding bit in the raw_status register to generate the intr1_sts interrupt. Read only.
0x1222C AID2_ee_sie_f_EV1_Enable_Set wo — (1 of 1, stride 0)
  [31:0] si_egr_iq_psi_sop_info — Sets the corresponding bit in the intr1_status register when set. Write only, self-clears.
0x12230 AID2_ee_sie_f_EV1_Enable_Clear wo — (1 of 1, stride 0)
  [31:0] si_egr_iq_psi_sop_info — Clears the corresponding bit in the intr1_status register when set. Write only, self-clears.
0x12234 AID2_ee_sie_f_EV0_Enabled_Status — (1 of 1, stride 0)
  [31:0] si_egr_iq_psi_sop_info — AND-ed raw_status bits with the corresponding bit in the enable_status register. Read only.
0x12238 AID2_ee_sie_f_EV1_Enabled_Status — (1 of 1, stride 0)
  [31:0] si_egr_iq_psi_sop_info — AND-ed raw_status bits with the corresponding bit in the intr1_status register. Read only.
0x122C0 AID2_ee_sie_g_Raw_Interrupt_Status — (1 of 1, stride 0)
  [15:0] si_egr_ctl_psi_sop_info — SI Egress CTL per channel SOP received from PSI
0x122C4 AID2_ee_sie_g_Raw_Set wo — (1 of 1, stride 0)
  [15:0] si_egr_ctl_psi_sop_info — Sets the corresponding bit in the raw_status register when set. Write only, self-clears.
0x122C8 AID2_ee_sie_g_Raw_Clear wo — (1 of 1, stride 0)
  [15:0] si_egr_ctl_psi_sop_info — Clears the corresponding bit in the raw_status register when set. Write only, self-clears.
0x122CC AID2_ee_sie_g_EV0_Enable_Status — (1 of 1, stride 0)
  [15:0] si_egr_ctl_psi_sop_info — When set allows the corresponding bit in the raw_status register to generate the intr_sts interrupt. Read only.
0x122D0 AID2_ee_sie_g_EV0_Enable_Set wo — (1 of 1, stride 0)
  [15:0] si_egr_ctl_psi_sop_info — Sets the corresponding bit in the enable register when set. Write only, self-clears.
0x122D4 AID2_ee_sie_g_EV0_Enable_Clear wo — (1 of 1, stride 0)
  [15:0] si_egr_ctl_psi_sop_info — Clears the corresponding bit in the enable register when set. Write only, self-clears.
0x122D8 AID2_ee_sie_g_EV1_Enable_Status — (1 of 1, stride 0)
  [15:0] si_egr_ctl_psi_sop_info — When set allows the corresponding bit in the raw_status register to generate the intr1_sts interrupt. Read only.
0x122DC AID2_ee_sie_g_EV1_Enable_Set wo — (1 of 1, stride 0)
  [15:0] si_egr_ctl_psi_sop_info — Sets the corresponding bit in the intr1_status register when set. Write only, self-clears.
0x122E0 AID2_ee_sie_g_EV1_Enable_Clear wo — (1 of 1, stride 0)
  [15:0] si_egr_ctl_psi_sop_info — Clears the corresponding bit in the intr1_status register when set. Write only, self-clears.
0x122E4 AID2_ee_sie_g_EV0_Enabled_Status — (1 of 1, stride 0)
  [15:0] si_egr_ctl_psi_sop_info — AND-ed raw_status bits with the corresponding bit in the enable_status register. Read only.
0x122E8 AID2_ee_sie_g_EV1_Enabled_Status — (1 of 1, stride 0)
  [15:0] si_egr_ctl_psi_sop_info — AND-ed raw_status bits with the corresponding bit in the intr1_status register. Read only.
0x12370 AID2_vbusclk_orig_reg — (1 of 1, stride 0)
  [19] orig_ee_19 — Undefined for AID2. Always read as 0.
  [18] orig_ee_18 — Undefined for AID2. Always read as 0.
  [17] orig_ee_17 — Undefined for AID2. Always read as 0.
  [16] orig_ee_16 — If set a bit is set in the ee_sie_g register.
  [15] orig_ee_15 — Undefined for AID2. Always read as 0.
  [14] orig_ee_14 — Undefined for AID2. Always read as 0.
  [13] orig_ee_13 — Undefined for AID2. Always read as 0.
  [12] orig_ee_12 — If set a bit is set in the ee_sie_f register.
  [11] orig_ee_11 — If set a bit is set in the ee_sie_e register.
  [10] orig_ee_10 — If set a bit is set in the ee_sie_d register.
  [9] orig_ee_9 — Undefined for AID2. Always read as 0.
  [8] orig_ee_8 — Undefined for AID2. Always read as 0.
  [7] orig_ee_7 — Undefined for AID2. Always read as 0.
  [6] orig_ee_6 — If set a bit is set in the ee_sii_h register.
  [5] orig_ee_5 — Undefined for AID2. Always read as 0.
  [4] orig_ee_4 — Undefined for AID2. Always read as 0.
  [3] orig_ee_3 — Undefined for AID2. Always read as 0.
  [2] orig_ee_2 — If set a bit is set in the ee_sii_g register.
  [1] orig_ee_1 — If set a bit is set in the ee_sii_f register.
  [0] orig_ee_0 — If set a bit is set in the ee_sii_e register.
